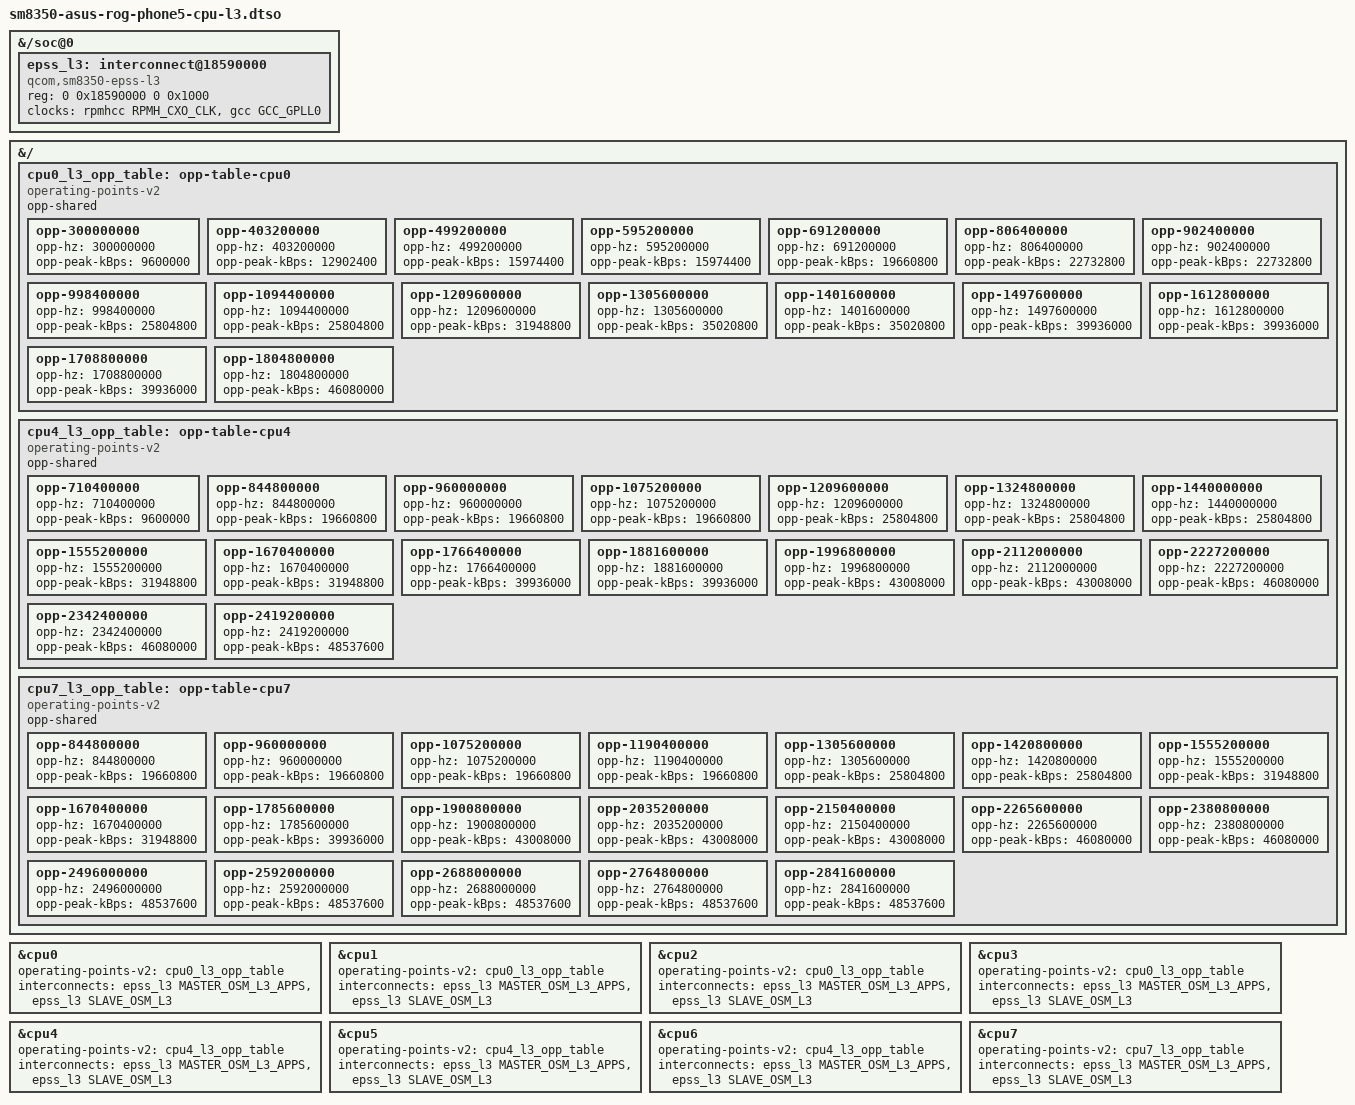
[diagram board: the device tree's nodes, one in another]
// SPDX-License-Identifier: BSD-3-Clause
/*
 * L3 cache frequency follows the CPU clusters (EPSS L3 vote), absent from
 * sm8350.dtsi: without it the L3 stayed at the firmware default whatever the
 * cores ran at. The generic qcom,epss-l3 driver votes the shared L3 (base +
 * 0x90); each CPU OPP carries an L3 peak bandwidth, kBps = L3 MHz x 32 x 1000
 * (32-byte node), and the interconnect core takes the maximum over all CPUs.
 * Core -> L3 steps are the stock ZS673KS tables (lahaina.dtsi cpu0/cpu4
 * core-dev-table); the prime core uses the big-core table, whose top step is
 * the stock prime compute floor (>= 2.4 GHz -> 1516.8 MHz). opp-hz values are
 * the EPSS LUT rows (cpufreq-hw drops OPPs that are not in the LUT).
 * cpufreq-hw needs the L3 provider, so CONFIG_INTERCONNECT_QCOM_OSM_L3=y.
 */
/dts-v1/;
/plugin/;

#include <dt-bindings/clock/qcom,gcc-sm8350.h>
#include <dt-bindings/clock/qcom,rpmh.h>
#include <dt-bindings/interconnect/qcom,osm-l3.h>

&{/soc@0} {
	#address-cells = <2>;
	#size-cells = <2>;

	epss_l3: interconnect@18590000 {
		compatible = "qcom,sm8350-epss-l3", "qcom,epss-l3";
		reg = <0 0x18590000 0 0x1000>;
		clocks = <&rpmhcc RPMH_CXO_CLK>, <&gcc GCC_GPLL0>;
		clock-names = "xo", "alternate";
		#interconnect-cells = <1>;
	};
};

&{/} {
	cpu0_l3_opp_table: opp-table-cpu0 {
		compatible = "operating-points-v2";
		opp-shared;

		opp-300000000 {
			opp-hz = /bits/ 64 <300000000>;
			opp-peak-kBps = <9600000>;
		};

		opp-403200000 {
			opp-hz = /bits/ 64 <403200000>;
			opp-peak-kBps = <12902400>;
		};

		opp-499200000 {
			opp-hz = /bits/ 64 <499200000>;
			opp-peak-kBps = <15974400>;
		};

		opp-595200000 {
			opp-hz = /bits/ 64 <595200000>;
			opp-peak-kBps = <15974400>;
		};

		opp-691200000 {
			opp-hz = /bits/ 64 <691200000>;
			opp-peak-kBps = <19660800>;
		};

		opp-806400000 {
			opp-hz = /bits/ 64 <806400000>;
			opp-peak-kBps = <22732800>;
		};

		opp-902400000 {
			opp-hz = /bits/ 64 <902400000>;
			opp-peak-kBps = <22732800>;
		};

		opp-998400000 {
			opp-hz = /bits/ 64 <998400000>;
			opp-peak-kBps = <25804800>;
		};

		opp-1094400000 {
			opp-hz = /bits/ 64 <1094400000>;
			opp-peak-kBps = <25804800>;
		};

		opp-1209600000 {
			opp-hz = /bits/ 64 <1209600000>;
			opp-peak-kBps = <31948800>;
		};

		opp-1305600000 {
			opp-hz = /bits/ 64 <1305600000>;
			opp-peak-kBps = <35020800>;
		};

		opp-1401600000 {
			opp-hz = /bits/ 64 <1401600000>;
			opp-peak-kBps = <35020800>;
		};

		opp-1497600000 {
			opp-hz = /bits/ 64 <1497600000>;
			opp-peak-kBps = <39936000>;
		};

		opp-1612800000 {
			opp-hz = /bits/ 64 <1612800000>;
			opp-peak-kBps = <39936000>;
		};

		opp-1708800000 {
			opp-hz = /bits/ 64 <1708800000>;
			opp-peak-kBps = <39936000>;
		};

		opp-1804800000 {
			opp-hz = /bits/ 64 <1804800000>;
			opp-peak-kBps = <46080000>;
		};
	};

	cpu4_l3_opp_table: opp-table-cpu4 {
		compatible = "operating-points-v2";
		opp-shared;

		opp-710400000 {
			opp-hz = /bits/ 64 <710400000>;
			opp-peak-kBps = <9600000>;
		};

		opp-844800000 {
			opp-hz = /bits/ 64 <844800000>;
			opp-peak-kBps = <19660800>;
		};

		opp-960000000 {
			opp-hz = /bits/ 64 <960000000>;
			opp-peak-kBps = <19660800>;
		};

		opp-1075200000 {
			opp-hz = /bits/ 64 <1075200000>;
			opp-peak-kBps = <19660800>;
		};

		opp-1209600000 {
			opp-hz = /bits/ 64 <1209600000>;
			opp-peak-kBps = <25804800>;
		};

		opp-1324800000 {
			opp-hz = /bits/ 64 <1324800000>;
			opp-peak-kBps = <25804800>;
		};

		opp-1440000000 {
			opp-hz = /bits/ 64 <1440000000>;
			opp-peak-kBps = <25804800>;
		};

		opp-1555200000 {
			opp-hz = /bits/ 64 <1555200000>;
			opp-peak-kBps = <31948800>;
		};

		opp-1670400000 {
			opp-hz = /bits/ 64 <1670400000>;
			opp-peak-kBps = <31948800>;
		};

		opp-1766400000 {
			opp-hz = /bits/ 64 <1766400000>;
			opp-peak-kBps = <39936000>;
		};

		opp-1881600000 {
			opp-hz = /bits/ 64 <1881600000>;
			opp-peak-kBps = <39936000>;
		};

		opp-1996800000 {
			opp-hz = /bits/ 64 <1996800000>;
			opp-peak-kBps = <43008000>;
		};

		opp-2112000000 {
			opp-hz = /bits/ 64 <2112000000>;
			opp-peak-kBps = <43008000>;
		};

		opp-2227200000 {
			opp-hz = /bits/ 64 <2227200000>;
			opp-peak-kBps = <46080000>;
		};

		opp-2342400000 {
			opp-hz = /bits/ 64 <2342400000>;
			opp-peak-kBps = <46080000>;
		};

		opp-2419200000 {
			opp-hz = /bits/ 64 <2419200000>;
			opp-peak-kBps = <48537600>;
		};
	};

	cpu7_l3_opp_table: opp-table-cpu7 {
		compatible = "operating-points-v2";
		opp-shared;

		opp-844800000 {
			opp-hz = /bits/ 64 <844800000>;
			opp-peak-kBps = <19660800>;
		};

		opp-960000000 {
			opp-hz = /bits/ 64 <960000000>;
			opp-peak-kBps = <19660800>;
		};

		opp-1075200000 {
			opp-hz = /bits/ 64 <1075200000>;
			opp-peak-kBps = <19660800>;
		};

		opp-1190400000 {
			opp-hz = /bits/ 64 <1190400000>;
			opp-peak-kBps = <19660800>;
		};

		opp-1305600000 {
			opp-hz = /bits/ 64 <1305600000>;
			opp-peak-kBps = <25804800>;
		};

		opp-1420800000 {
			opp-hz = /bits/ 64 <1420800000>;
			opp-peak-kBps = <25804800>;
		};

		opp-1555200000 {
			opp-hz = /bits/ 64 <1555200000>;
			opp-peak-kBps = <31948800>;
		};

		opp-1670400000 {
			opp-hz = /bits/ 64 <1670400000>;
			opp-peak-kBps = <31948800>;
		};

		opp-1785600000 {
			opp-hz = /bits/ 64 <1785600000>;
			opp-peak-kBps = <39936000>;
		};

		opp-1900800000 {
			opp-hz = /bits/ 64 <1900800000>;
			opp-peak-kBps = <43008000>;
		};

		opp-2035200000 {
			opp-hz = /bits/ 64 <2035200000>;
			opp-peak-kBps = <43008000>;
		};

		opp-2150400000 {
			opp-hz = /bits/ 64 <2150400000>;
			opp-peak-kBps = <43008000>;
		};

		opp-2265600000 {
			opp-hz = /bits/ 64 <2265600000>;
			opp-peak-kBps = <46080000>;
		};

		opp-2380800000 {
			opp-hz = /bits/ 64 <2380800000>;
			opp-peak-kBps = <46080000>;
		};

		opp-2496000000 {
			opp-hz = /bits/ 64 <2496000000>;
			opp-peak-kBps = <48537600>;
		};

		opp-2592000000 {
			opp-hz = /bits/ 64 <2592000000>;
			opp-peak-kBps = <48537600>;
		};

		opp-2688000000 {
			opp-hz = /bits/ 64 <2688000000>;
			opp-peak-kBps = <48537600>;
		};

		opp-2764800000 {
			opp-hz = /bits/ 64 <2764800000>;
			opp-peak-kBps = <48537600>;
		};

		opp-2841600000 {
			opp-hz = /bits/ 64 <2841600000>;
			opp-peak-kBps = <48537600>;
		};
	};
};

&cpu0 {
	operating-points-v2 = <&cpu0_l3_opp_table>;
	interconnects = <&epss_l3 MASTER_OSM_L3_APPS &epss_l3 SLAVE_OSM_L3>;
};

&cpu1 {
	operating-points-v2 = <&cpu0_l3_opp_table>;
	interconnects = <&epss_l3 MASTER_OSM_L3_APPS &epss_l3 SLAVE_OSM_L3>;
};

&cpu2 {
	operating-points-v2 = <&cpu0_l3_opp_table>;
	interconnects = <&epss_l3 MASTER_OSM_L3_APPS &epss_l3 SLAVE_OSM_L3>;
};

&cpu3 {
	operating-points-v2 = <&cpu0_l3_opp_table>;
	interconnects = <&epss_l3 MASTER_OSM_L3_APPS &epss_l3 SLAVE_OSM_L3>;
};

&cpu4 {
	operating-points-v2 = <&cpu4_l3_opp_table>;
	interconnects = <&epss_l3 MASTER_OSM_L3_APPS &epss_l3 SLAVE_OSM_L3>;
};

&cpu5 {
	operating-points-v2 = <&cpu4_l3_opp_table>;
	interconnects = <&epss_l3 MASTER_OSM_L3_APPS &epss_l3 SLAVE_OSM_L3>;
};

&cpu6 {
	operating-points-v2 = <&cpu4_l3_opp_table>;
	interconnects = <&epss_l3 MASTER_OSM_L3_APPS &epss_l3 SLAVE_OSM_L3>;
};

&cpu7 {
	operating-points-v2 = <&cpu7_l3_opp_table>;
	interconnects = <&epss_l3 MASTER_OSM_L3_APPS &epss_l3 SLAVE_OSM_L3>;
};
